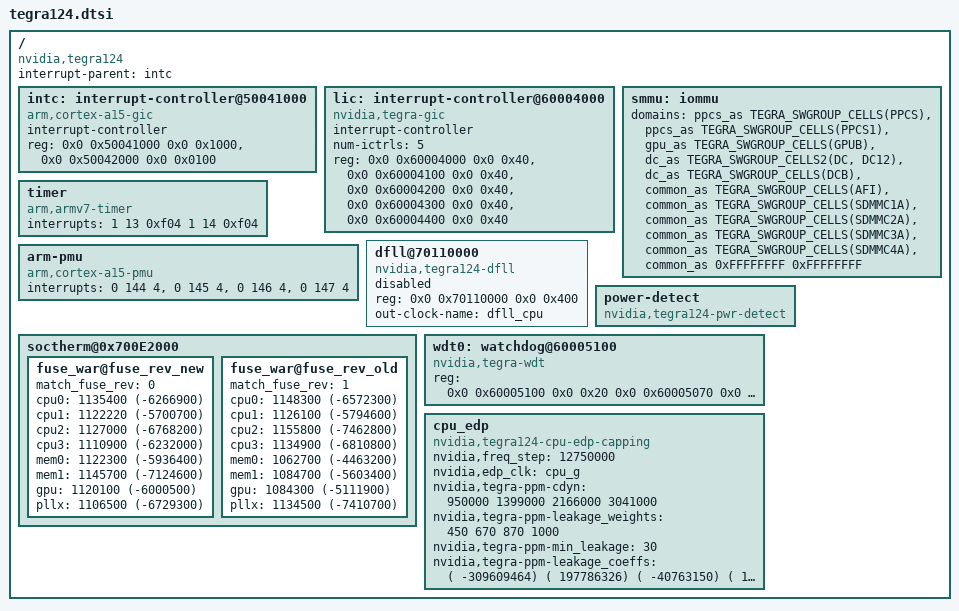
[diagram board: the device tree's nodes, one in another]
/*
 * arch/arm/boot/dts/tegra124.dtsi
 *
 * Copyright (c) 2013-2014, NVIDIA CORPORATION. All rights reserved.
 *
 * This program is free software; you can redistribute it and/or modify it
 * under the terms and conditions of the GNU General Public License,
 * version 2, as published by the Free Software Foundation.
 *
 * This program is distributed in the hope it will be useful, but WITHOUT
 * ANY WARRANTY; without even the implied warranty of MERCHANTABILITY or
 * FITNESS FOR A PARTICULAR PURPOSE.  See the GNU General Public License for
 * more details.
 *
 * You should have received a copy of the GNU General Public License
 * along with this program.  If not, see <http://www.gnu.org/licenses/>.
 */

#include <dt-bindings/gpio/tegra-gpio.h>
#include <dt-bindings/memory/tegra-swgroup.h>
#include <dt-bindings/input/input.h>
#include <dt-bindings/interrupt-controller/arm-gic.h>

#include "tegra124-soc.dtsi"
#include "tegra124-platforms/tegra124-soctherm.dtsi"
#include "tegra124-platforms/tegra124-bthrot-cdev.dtsi"
#include "tegra124-platforms/tegra124-prods.dtsi"

/ {
	compatible = "nvidia,tegra124";
	interrupt-parent = <&intc>;
	#address-cells = <2>;
	#size-cells = <2>;

	intc: interrupt-controller@50041000 {
		compatible = "arm,cortex-a15-gic";
		interrupt-controller;
		#interrupt-cells = <3>;
		reg = <0x0 0x50041000 0x0 0x1000>,
		      <0x0 0x50042000 0x0 0x0100>;
	};

	lic: interrupt-controller@60004000 {
		compatible = "nvidia,tegra-gic";
		interrupt-controller;
		num-ictrls = <5>;
		reg = <0x0 0x60004000 0x0 0x40>,
		      <0x0 0x60004100 0x0 0x40>,
		      <0x0 0x60004200 0x0 0x40>,
		      <0x0 0x60004300 0x0 0x40>,
		      <0x0 0x60004400 0x0 0x40>;
        };

	smmu: iommu {
		domains = <
			&ppcs_as TEGRA_SWGROUP_CELLS(PPCS)
			&ppcs_as TEGRA_SWGROUP_CELLS(PPCS1)
			&gpu_as TEGRA_SWGROUP_CELLS(GPUB)
			&dc_as TEGRA_SWGROUP_CELLS2(DC, DC12)
			&dc_as TEGRA_SWGROUP_CELLS(DCB)
			&common_as TEGRA_SWGROUP_CELLS(AFI)
			&common_as TEGRA_SWGROUP_CELLS(SDMMC1A)
			&common_as TEGRA_SWGROUP_CELLS(SDMMC2A)
			&common_as TEGRA_SWGROUP_CELLS(SDMMC3A)
			&common_as TEGRA_SWGROUP_CELLS(SDMMC4A)
			&common_as 0xFFFFFFFF 0xFFFFFFFF>;
	};

	timer {
		compatible = "arm,armv7-timer";
		interrupts = <1 13 0xf04
			      1 14 0xf04>;
	};

	arm-pmu {
		compatible = "arm,cortex-a15-pmu";
		interrupts = <0 144 4>,
			     <0 145 4>,
			     <0 146 4>,
			     <0 147 4>;
	};

	dfll@70110000 {
			compatible = "nvidia,tegra124-dfll";
			reg = <0x0 0x70110000 0x0 0x400>;
			out-clock-name="dfll_cpu";
			status = "disabled";
	};

	power-detect {
		compatible = "nvidia,tegra124-pwr-detect";
	};

	soctherm@0x700E2000 {
		fuse_war@fuse_rev_new { /* CP1/CP2 */
			device_type = "fuse_war";
			match_fuse_rev = <0>; /* see xx_fuse_offsets.h */
			cpu0 = <1135400  (-6266900)>;
			cpu1 = <1122220  (-5700700)>;
			cpu2 = <1127000  (-6768200)>;
			cpu3 = <1110900  (-6232000)>;
			mem0 = <1122300  (-5936400)>;
			mem1 = <1145700  (-7124600)>;
			gpu  = <1120100  (-6000500)>;
			pllx = <1106500  (-6729300)>;
		};
		fuse_war@fuse_rev_old { /* CP/FT */
			device_type = "fuse_war";
			match_fuse_rev = <1>; /* see xx_fuse_offsets.h */
			cpu0 = <1148300  (-6572300)>;
			cpu1 = <1126100  (-5794600)>;
			cpu2 = <1155800  (-7462800)>;
			cpu3 = <1134900  (-6810800)>;
			mem0 = <1062700  (-4463200)>;
			mem1 = <1084700  (-5603400)>;
			gpu  = <1084300  (-5111900)>;
			pllx = <1134500  (-7410700)>;
		};
	};

	/* WDT0 using TMR7 as timing reference */
	wdt0: watchdog@60005100 {
		compatible = "nvidia,tegra-wdt";
		reg = <0x0 0x60005100 0x0 0x20		/* WDT0 registers */
			0x0 0x60005070 0x0 0x8>;	/* TMR7 registers */
	};

	cpu_edp {
		compatible = "nvidia,tegra124-cpu-edp-capping";
		nvidia,freq_step = <12750000>;
		nvidia,edp_clk = "cpu_g";
		nvidia,tegra-ppm-cdyn = <950000 1399000 2166000 3041000>;
		nvidia,tegra-ppm-leakage_weights = <450 670 870 1000>;
		nvidia,tegra-ppm-min_leakage = <30>;
		nvidia,tegra-ppm-leakage_coeffs = <
			  ( -309609464) (  197786326) ( -40763150) (  1613941)
			  (  964716269) ( -569081375) ( 115781607) ( -4206296)
			  ( -994324790) (  529664031) (-106360108) (  3454033)
			  (  343209442) ( -160577505) (  31928605) (  -895157)
			  (  616319664) ( -637007187) ( 137759592) ( -7194133)
			  (-1853817283) ( 1896032851) (-407407611) ( 20868220)
			  ( 1824097131) (-1831611624) ( 390753403) (-19530122)
			  ( -589155245) (  578838526) (-122655676) (  5985577)
			  ( -439994037) (  455845250) (-104097013) (  6191899)
			  ( 1354650774) (-1395561938) ( 318665647) (-18886906)
			  (-1361677255) ( 1390149678) (-317474532) ( 18728266)
			  (  447877887) ( -451382027) ( 103201434) ( -6046692)
			  (   56797556) (  -59779544) (  13810295) (  -848290)
			  ( -175867301) (  184753957) ( -42708242) (  2621537)
			  (  177626357) ( -185996541) (  43029384) ( -2638283)
			  (  -58587547) (   61075322) ( -14145853) (   865351)
			>;

	};

};
